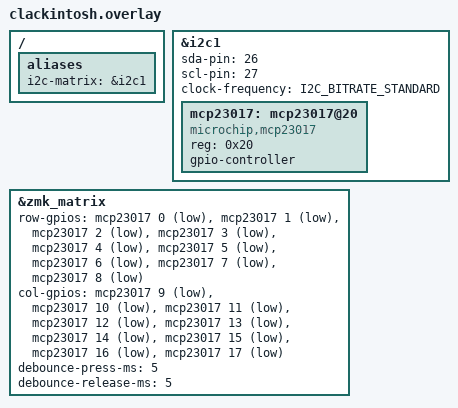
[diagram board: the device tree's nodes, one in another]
/ {
    aliases {
        i2c-matrix = &i2c1;
    };
};

&i2c1 {
    status = "okay";
    sda-pin = <26>;
    scl-pin = <27>;
    clock-frequency = <I2C_BITRATE_STANDARD>;

    mcp23017: mcp23017@20 {
        compatible = "microchip,mcp23017";
        reg = <0x20>;
        gpio-controller;
        #gpio-cells = <2>;
    };
};

&zmk_matrix {
    row-gpios = <
        &mcp23017 0 GPIO_ACTIVE_LOW
        &mcp23017 1 GPIO_ACTIVE_LOW
        &mcp23017 2 GPIO_ACTIVE_LOW
        &mcp23017 3 GPIO_ACTIVE_LOW
        &mcp23017 4 GPIO_ACTIVE_LOW
        &mcp23017 5 GPIO_ACTIVE_LOW
        &mcp23017 6 GPIO_ACTIVE_LOW
        &mcp23017 7 GPIO_ACTIVE_LOW
        &mcp23017 8 GPIO_ACTIVE_LOW
    >;

    col-gpios = <
        &mcp23017 9  GPIO_ACTIVE_LOW
        &mcp23017 10 GPIO_ACTIVE_LOW
        &mcp23017 11 GPIO_ACTIVE_LOW
        &mcp23017 12 GPIO_ACTIVE_LOW
        &mcp23017 13 GPIO_ACTIVE_LOW
        &mcp23017 14 GPIO_ACTIVE_LOW
        &mcp23017 15 GPIO_ACTIVE_LOW
        &mcp23017 16 GPIO_ACTIVE_LOW
        &mcp23017 17 GPIO_ACTIVE_LOW
    >;

    debounce-press-ms = <5>;
    debounce-release-ms = <5>;
};
